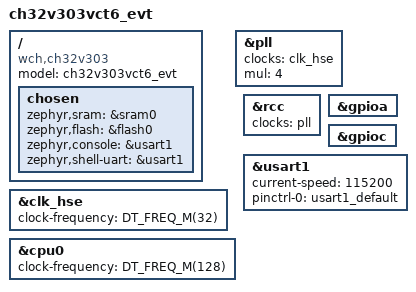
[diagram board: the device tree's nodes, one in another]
/*
 * Copyright (c) 2025 Bootlin
 * SPDX-License-Identifier: Apache-2.0
 */

/dts-v1/;

#include <wch/ch32v303/ch32v303vct.dtsi>
#include <zephyr/dt-bindings/gpio/gpio.h>
#include <zephyr/dt-bindings/input/input-event-codes.h>
#include "ch32v303vct6_evt-pinctrl.dtsi"

/ {
	model = "ch32v303vct6_evt";
	compatible = "wch,ch32v303";

	chosen {
		zephyr,sram = &sram0;
		zephyr,flash = &flash0;
		zephyr,console = &usart1;
		zephyr,shell-uart = &usart1;
	};
};

&clk_hse {
	clock-frequency = <DT_FREQ_M(32)>;
	status = "okay";
};

&pll {
	clocks = <&clk_hse>;
	/*
	 * 144MHz requires PLLXTPRE (HSE/2), which is not yet supported
	 * in the DT binding. Use mul=4 (32*4=128MHz) for now.
	 */
	mul = <4>;
	status = "okay";
};

&cpu0 {
	clock-frequency = <DT_FREQ_M(128)>;
};

&rcc {
	clocks = <&pll>;
};

&gpioa {
	status = "okay";
};

&gpioc {
	status = "okay";
};

&usart1 {
	status = "okay";
	current-speed = <115200>;
	pinctrl-0 = <&usart1_default>;
	pinctrl-names = "default";
};
